# K32W041AM register map
Vendor: nxp.com; File version: 1.0
CPU: CM4 r0p1, little endian, MPU, no FPU, VTOR, 3 interrupt priority bits
Registers are 32-bit, read-write, reset 0x0 unless marked. A register's access mark holds for its fields unless they carry their own. Offsets are from the block's base; [hi:lo] are bit positions; {n}, {i} and the like mark numbered series; 'fields as' and 'values as' point back to an identical list.

## IOCON — This is the description of component input mux. . More details will follow.
Base 0x4000F000
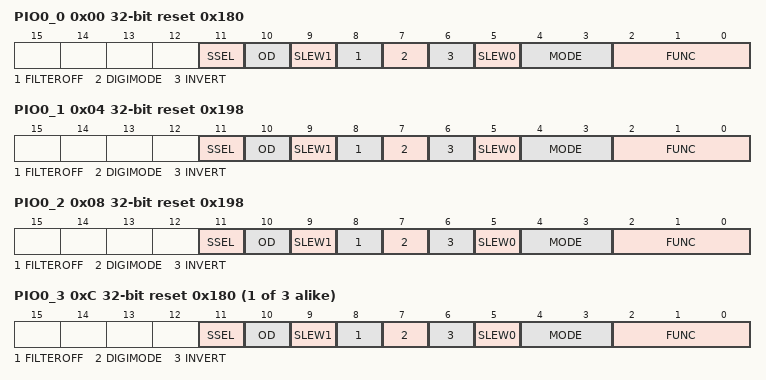
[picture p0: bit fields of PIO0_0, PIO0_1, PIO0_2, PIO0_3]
0x00 PIO0_0 reset 0x180 — Configuration array for PIO0 to PIO21. PIO[10] and PIO[11] use a different IO cell type to the other PIO pins and so there are some differences in the bit field descriptions of the PIO register for these Ios. Reset values vary depending on whether the IO is configured with a pull-up or pull-down resistor as default. The value is also affected by the IO type. Reset value 0x180 for PIO 0,3,4,5,8,9,12,13,14,15,16,21. Reset value 0x198 for PIO 1,2,6,7,17,18,19,20. Reset value 0x188 for PIO 10,11.
  [11] SSEL — IO Clamping Function
    0=DISABLED (This bit controls the IO clamping function is disabled.); 1=ENABLED (This bit controls the IO clamping function is enabled.)
  [10] OD — Controls open-drain mode.
    0=NORMAL (Normal. Normal push-pull output); 1=OPEN_DRAIN (Open-drain. Simulated open-drain output (high drive disabled).)
  [9] SLEW1 — Driver Slew Rate. This bit is used in combination with SLEW0. The higher [SLEW1,SLEW0], the quicker the slew rate.
    0=DISABLED (Driver slew1 rate is disabled.); 1=ENABLED (Driver slew1 rate is enabled.)
  [8] FILTEROFF — Controls Input Glitch Filter.
    0=ENABLED (Filter enabled. Noise pulses below approximately 1 ns are filtered out.); 1=DISABLED (Filter disabled. No input filtering is done.)
  [7] DIGIMODE — Select Analog/Digital Mode. 0 Analog mode. 1 Digital mode. When in analog mode, the receiver path in the IO cell is disabled. In this mode, it is essential that the digital function (e.g. GPIO) is not configured as an output. Otherwise it may conflict with analog stuff (loopback of digital on analog input). In other words, the digital output is not automatically disabled when the IO is in analog mode. As a consequence, it is not possible to disable the receiver path when the IO is used for digital output purpose.
    0=ANALOG (Analog mode, digital input is disabled.); 1=DIGITAL (Digital mode, digital input is enabled.)
  [6] INVERT — Input Polarity.
    0=DISABLED (Disabled. Input function is not inverted.); 1=ENABLED (Enabled. Input function is inverted.)
  [5] SLEW0 — This bit field is used in combination with SLEW1. The higher [SLEW1,SLEW0] the quicker the IO cell slew rate.
    0=DISABLED (Driver slew0 rate is disabled.); 1=ENABLED (Driver slew0 rate is enabled.)
  [4:3] MODE — Select function mode (on-chip pull-up/pull-down resistor control). For MFIO type ONLY (all PIOs except PIO10 & 11): 0x0 : Pull-up. Pull-up resistor enabled. 0x1 : Repeater mode (bus keeper) 0x2 : Plain Input 0x3 : Pull-down. Pull-down resistor enabled. Note: When the register is related to a general purpose MFIO type pad (that is all PIOs except PIO10 & 11) - Bit [3] (of the register) is connected to EPD (enable pull-down) input of the MFIO pad. - Bit [4] (of the register) is connected to EPUN (enable pull-up NOT) input of MFIO pad.
    0=PULL_UP (Pull-up. Pull-up resistor enabled.); 1=REPEATER (Repeater. Repeater mode (bus keeper).); 2=INACTIVE (Inactive. Plain Input.); 3=PULL_DOWN (Pull-down. Pull-down resistor enabled.)
  [2:0] FUNC — Select digital function assigned to this pin.
    {v}=ALT{v} (Alternative connection {v}.) (v=0..7)
0x04 PIO0_1 reset 0x198 — Configuration array for PIO0 to PIO21. PIO[10] and PIO[11] use a different IO cell type to the other PIO pins and so there are some differences in the bit field descriptions of the PIO register for these Ios. Reset values vary depending on whether the IO is configured with a pull-up or pull-down resistor as default. The value is also affected by the IO type. Reset value 0x180 for PIO 0,3,4,5,8,9,12,13,14,15,16,21. Reset value 0x198 for PIO 1,2,6,7,17,18,19,20. Reset value 0x188 for PIO 10,11.
  fields as PIO0_0
0x08 PIO0_2 reset 0x198 — Configuration array for PIO0 to PIO21. PIO[10] and PIO[11] use a different IO cell type to the other PIO pins and so there are some differences in the bit field descriptions of the PIO register for these Ios. Reset values vary depending on whether the IO is configured with a pull-up or pull-down resistor as default. The value is also affected by the IO type. Reset value 0x180 for PIO 0,3,4,5,8,9,12,13,14,15,16,21. Reset value 0x198 for PIO 1,2,6,7,17,18,19,20. Reset value 0x188 for PIO 10,11.
  fields as PIO0_0
{0x0+4i} PIO0_{i} reset 0x180 (i=3..5) — Configuration array for PIO0 to PIO21. PIO[10] and PIO[11] use a different IO cell type to the other PIO pins and so there are some differences in the bit field descriptions of the PIO register for these Ios. Reset values vary depending on whether the IO is configured with a pull-up or pull-down resistor as default. The value is also affected by the IO type. Reset value 0x180 for PIO 0,3,4,5,8,9,12,13,14,15,16,21. Reset value 0x198 for PIO 1,2,6,7,17,18,19,20. Reset value 0x188 for PIO 10,11.
  fields as PIO0_0
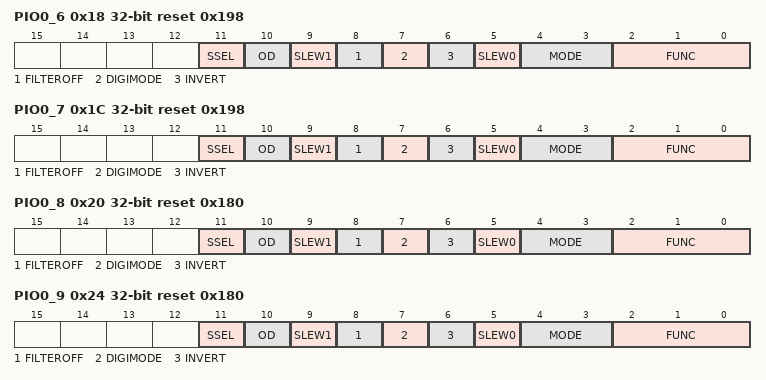
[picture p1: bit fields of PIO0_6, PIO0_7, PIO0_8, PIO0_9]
0x18 PIO0_6 reset 0x198 — Configuration array for PIO0 to PIO21. PIO[10] and PIO[11] use a different IO cell type to the other PIO pins and so there are some differences in the bit field descriptions of the PIO register for these Ios. Reset values vary depending on whether the IO is configured with a pull-up or pull-down resistor as default. The value is also affected by the IO type. Reset value 0x180 for PIO 0,3,4,5,8,9,12,13,14,15,16,21. Reset value 0x198 for PIO 1,2,6,7,17,18,19,20. Reset value 0x188 for PIO 10,11.
  fields as PIO0_0
0x1C PIO0_7 reset 0x198 — Configuration array for PIO0 to PIO21. PIO[10] and PIO[11] use a different IO cell type to the other PIO pins and so there are some differences in the bit field descriptions of the PIO register for these Ios. Reset values vary depending on whether the IO is configured with a pull-up or pull-down resistor as default. The value is also affected by the IO type. Reset value 0x180 for PIO 0,3,4,5,8,9,12,13,14,15,16,21. Reset value 0x198 for PIO 1,2,6,7,17,18,19,20. Reset value 0x188 for PIO 10,11.
  fields as PIO0_0
0x20 PIO0_8 reset 0x180 — Configuration array for PIO0 to PIO21. PIO[10] and PIO[11] use a different IO cell type to the other PIO pins and so there are some differences in the bit field descriptions of the PIO register for these Ios. Reset values vary depending on whether the IO is configured with a pull-up or pull-down resistor as default. The value is also affected by the IO type. Reset value 0x180 for PIO 0,3,4,5,8,9,12,13,14,15,16,21. Reset value 0x198 for PIO 1,2,6,7,17,18,19,20. Reset value 0x188 for PIO 10,11.
  fields as PIO0_0
0x24 PIO0_9 reset 0x180 — Configuration array for PIO0 to PIO21. PIO[10] and PIO[11] use a different IO cell type to the other PIO pins and so there are some differences in the bit field descriptions of the PIO register for these Ios. Reset values vary depending on whether the IO is configured with a pull-up or pull-down resistor as default. The value is also affected by the IO type. Reset value 0x180 for PIO 0,3,4,5,8,9,12,13,14,15,16,21. Reset value 0x198 for PIO 1,2,6,7,17,18,19,20. Reset value 0x188 for PIO 10,11.
  fields as PIO0_0
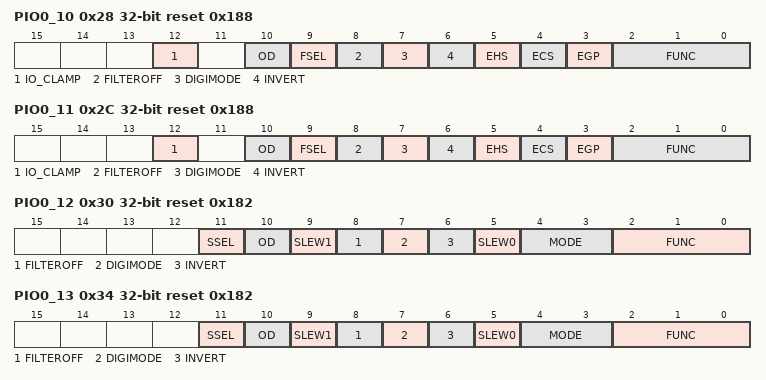
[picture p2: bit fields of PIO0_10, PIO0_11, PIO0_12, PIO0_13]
0x28 PIO0_10 reset 0x188 — Configuration array for PIO0 to PIO21. PIO[10] and PIO[11] use a different IO cell type to the other PIO pins and so there are some differences in the bit field descriptions of the PIO register for these Ios. Reset values vary depending on whether the IO is configured with a pull-up or pull-down resistor as default. The value is also affected by the IO type. Reset value 0x180 for PIO 0,3,4,5,8,9,12,13,14,15,16,21. Reset value 0x198 for PIO 1,2,6,7,17,18,19,20. Reset value 0x188 for PIO 10,11.
  [12] IO_CLAMP — Assert to freeze the IO. Also needs SYSCON:RETENTIONCTRL set as well. Useful in power down mode. This mode is held through power down cycle. Before releasing this mode on a wake-up, ensure the IO is set to the required direction and value using GPIO DIR and PIN registers.
    0=DISABLED (IO_CLAMP is disabled.); 1=ENABLED (IO_CLAMP is enabled.)
  [10] OD — Controls open-drain mode.
    values as PIO0_0.OD
  [9] FSEL — Control Input Glitch Filter.
    0=DISABLED (Noise pulses below approximately 50ns are filtered out.); 1=ENABLED (Noise pulses below approximately 10 ns are filtered out. If IO is in GPIO mode this control bit is irrelevant, a 3 ns filter is used.)
  [8] FILTEROFF — Controls Input Glitch Filter.
    values as PIO0_0.FILTEROFF
  [7] DIGIMODE — Select Analog/Digital Mode. 0 Analog mode. 1 Digital mode. When in analog mode, the receiver path in the IO cell is disabled. In this mode, it is essential that the digital function (e.g. GPIO) is not configured as an output. Otherwise it may conflict with analog stuff (loopback of digital on analog input). In other words, the digital output is not automatically disabled when the IO is in analog mode. As a consequence, it is not possible to disable the receiver path when the IO is used for digital output purpose.
    values as PIO0_0.DIGIMODE
  [6] INVERT — Input Polarity.
    values as PIO0_0.INVERT
  [5] EHS — Speed selection. When IO is in GPIO mode set 1 for high speed GPIO, 0 for low speed GPIO. For IIC mode, this bit has no effect and the IO is always in low speed.
    0=DISABLED (low speed for GPIO mode or i2c mode.); 1=ENABLED (High speed for GPIO mode.)
  [4] ECS — Pull-up current source enable when set. When IO is is IIC mode (EGP=0) and ECS is low, the IO cell is an open drain cell.
    0=DISABLED (Pull-up current source disabled.); 1=ENABLED (Pull-up current source enabled.)
  [3] EGP — GPIO Mode of IO Cell.
    0=IIC (IIC mode.); 1=GPIO (GPIO mode.)
  [2:0] FUNC — Select digital function assigned to this pin.
    {v}=ALT{v} (Alternative connection {v}.) (v=0..7)
0x2C PIO0_11 reset 0x188 — Configuration array for PIO0 to PIO21. PIO[10] and PIO[11] use a different IO cell type to the other PIO pins and so there are some differences in the bit field descriptions of the PIO register for these Ios. Reset values vary depending on whether the IO is configured with a pull-up or pull-down resistor as default. The value is also affected by the IO type. Reset value 0x180 for PIO 0,3,4,5,8,9,12,13,14,15,16,21. Reset value 0x198 for PIO 1,2,6,7,17,18,19,20. Reset value 0x188 for PIO 10,11.
  fields as PIO0_10
0x30 PIO0_12 reset 0x182 — Configuration array for PIO0 to PIO21. PIO[10] and PIO[11] use a different IO cell type to the other PIO pins and so there are some differences in the bit field descriptions of the PIO register for these Ios. Reset values vary depending on whether the IO is configured with a pull-up or pull-down resistor as default. The value is also affected by the IO type. Reset value 0x180 for PIO 0,3,4,5,8,9,12,13,14,15,16,21. Reset value 0x198 for PIO 1,2,6,7,17,18,19,20. Reset value 0x188 for PIO 10,11.
  fields as PIO0_0
0x34 PIO0_13 reset 0x182 — Configuration array for PIO0 to PIO21. PIO[10] and PIO[11] use a different IO cell type to the other PIO pins and so there are some differences in the bit field descriptions of the PIO register for these Ios. Reset values vary depending on whether the IO is configured with a pull-up or pull-down resistor as default. The value is also affected by the IO type. Reset value 0x180 for PIO 0,3,4,5,8,9,12,13,14,15,16,21. Reset value 0x198 for PIO 1,2,6,7,17,18,19,20. Reset value 0x188 for PIO 10,11.
  fields as PIO0_0
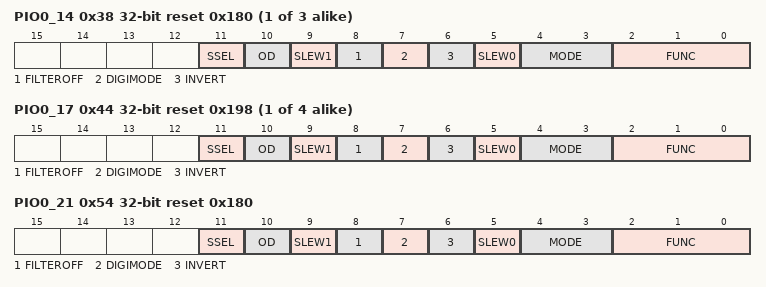
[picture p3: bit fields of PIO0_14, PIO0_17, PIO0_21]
{0x0+4i} PIO0_{i} reset 0x180 (i=14..16) — Configuration array for PIO0 to PIO21. PIO[10] and PIO[11] use a different IO cell type to the other PIO pins and so there are some differences in the bit field descriptions of the PIO register for these Ios. Reset values vary depending on whether the IO is configured with a pull-up or pull-down resistor as default. The value is also affected by the IO type. Reset value 0x180 for PIO 0,3,4,5,8,9,12,13,14,15,16,21. Reset value 0x198 for PIO 1,2,6,7,17,18,19,20. Reset value 0x188 for PIO 10,11.
  fields as PIO0_0
{0x0+4i} PIO0_{i} reset 0x198 (i=17..20) — Configuration array for PIO0 to PIO21. PIO[10] and PIO[11] use a different IO cell type to the other PIO pins and so there are some differences in the bit field descriptions of the PIO register for these Ios. Reset values vary depending on whether the IO is configured with a pull-up or pull-down resistor as default. The value is also affected by the IO type. Reset value 0x180 for PIO 0,3,4,5,8,9,12,13,14,15,16,21. Reset value 0x198 for PIO 1,2,6,7,17,18,19,20. Reset value 0x188 for PIO 10,11.
  fields as PIO0_0
0x54 PIO0_21 reset 0x180 — Configuration array for PIO0 to PIO21. PIO[10] and PIO[11] use a different IO cell type to the other PIO pins and so there are some differences in the bit field descriptions of the PIO register for these Ios. Reset values vary depending on whether the IO is configured with a pull-up or pull-down resistor as default. The value is also affected by the IO type. Reset value 0x180 for PIO 0,3,4,5,8,9,12,13,14,15,16,21. Reset value 0x198 for PIO 1,2,6,7,17,18,19,20. Reset value 0x188 for PIO 10,11.
  fields as PIO0_0
